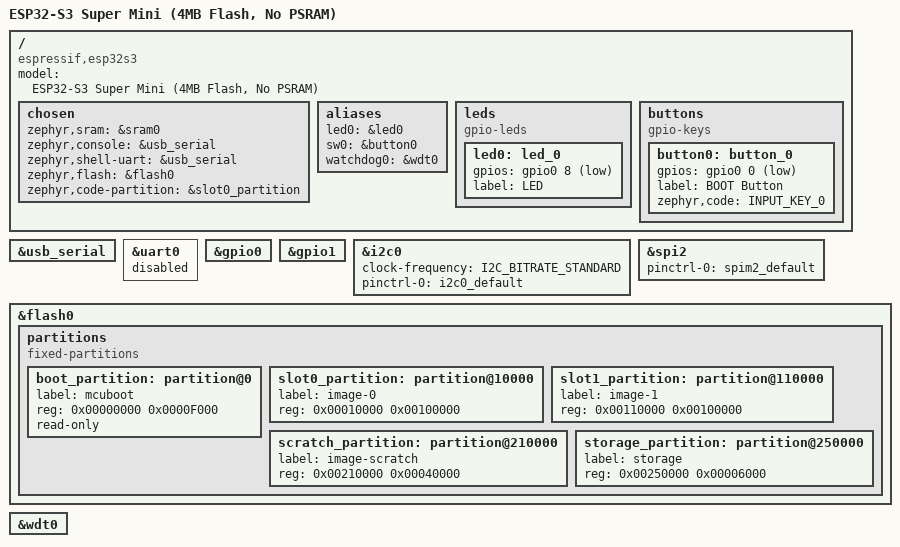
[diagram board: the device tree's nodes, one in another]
/dts-v1/;

#include <espressif/esp32s3/esp32s3_fn8.dtsi>
#include "esp32s3_super_mini-pinctrl.dtsi"
#include <zephyr/dt-bindings/input/input-event-codes.h>

/ {
	model = "ESP32-S3 Super Mini (4MB Flash, No PSRAM)";
	compatible = "espressif,esp32s3";

	chosen {
		zephyr,sram = &sram0;
		zephyr,console = &usb_serial;
		zephyr,shell-uart = &usb_serial;
		zephyr,flash = &flash0;
		zephyr,code-partition = &slot0_partition;
	};

	aliases {
		led0 = &led0;
		sw0 = &button0;
		watchdog0 = &wdt0;
	};

	leds {
		compatible = "gpio-leds";
		led0: led_0 {
			gpios = <&gpio0 8 GPIO_ACTIVE_LOW>;
			label = "LED";
		};
	};

	buttons {
		compatible = "gpio-keys";
		button0: button_0 {
			gpios = <&gpio0 0 (GPIO_PULL_UP | GPIO_ACTIVE_LOW)>;
			label = "BOOT Button";
			zephyr,code = <INPUT_KEY_0>;
		};
	};
};

&usb_serial {
	status = "okay";
};

&uart0 {
	status = "disabled";
};

&gpio0 {
	status = "okay";
};

&gpio1 {
	status = "okay";
};

&i2c0 {
	status = "okay";
	clock-frequency = <I2C_BITRATE_STANDARD>;
	pinctrl-0 = <&i2c0_default>;
	pinctrl-names = "default";
};

&spi2 {
	#address-cells = <1>;
	#size-cells = <0>;
	status = "okay";
	pinctrl-0 = <&spim2_default>;
	pinctrl-names = "default";
};

&flash0 {
	status = "okay";
	partitions {
		compatible = "fixed-partitions";
		#address-cells = <1>;
		#size-cells = <1>;

		/* Reserve 60kB for the bootloader */
		boot_partition: partition@0 {
			label = "mcuboot";
			reg = <0x00000000 0x0000F000>;
			read-only;
		};

		/* Reserve 1024kB for the application in slot 0 */
		slot0_partition: partition@10000 {
			label = "image-0";
			reg = <0x00010000 0x00100000>;
		};

		/* Reserve 1024kB for the application in slot 1 */
		slot1_partition: partition@110000 {
			label = "image-1";
			reg = <0x00110000 0x00100000>;
		};

		/* Reserve 256kB for the scratch partition */
		scratch_partition: partition@210000 {
			label = "image-scratch";
			reg = <0x00210000 0x00040000>;
		};

		storage_partition: partition@250000 {
			label = "storage";
			reg = <0x00250000 0x00006000>;
		};
	};
};

&wdt0 {
	status = "okay";
};
